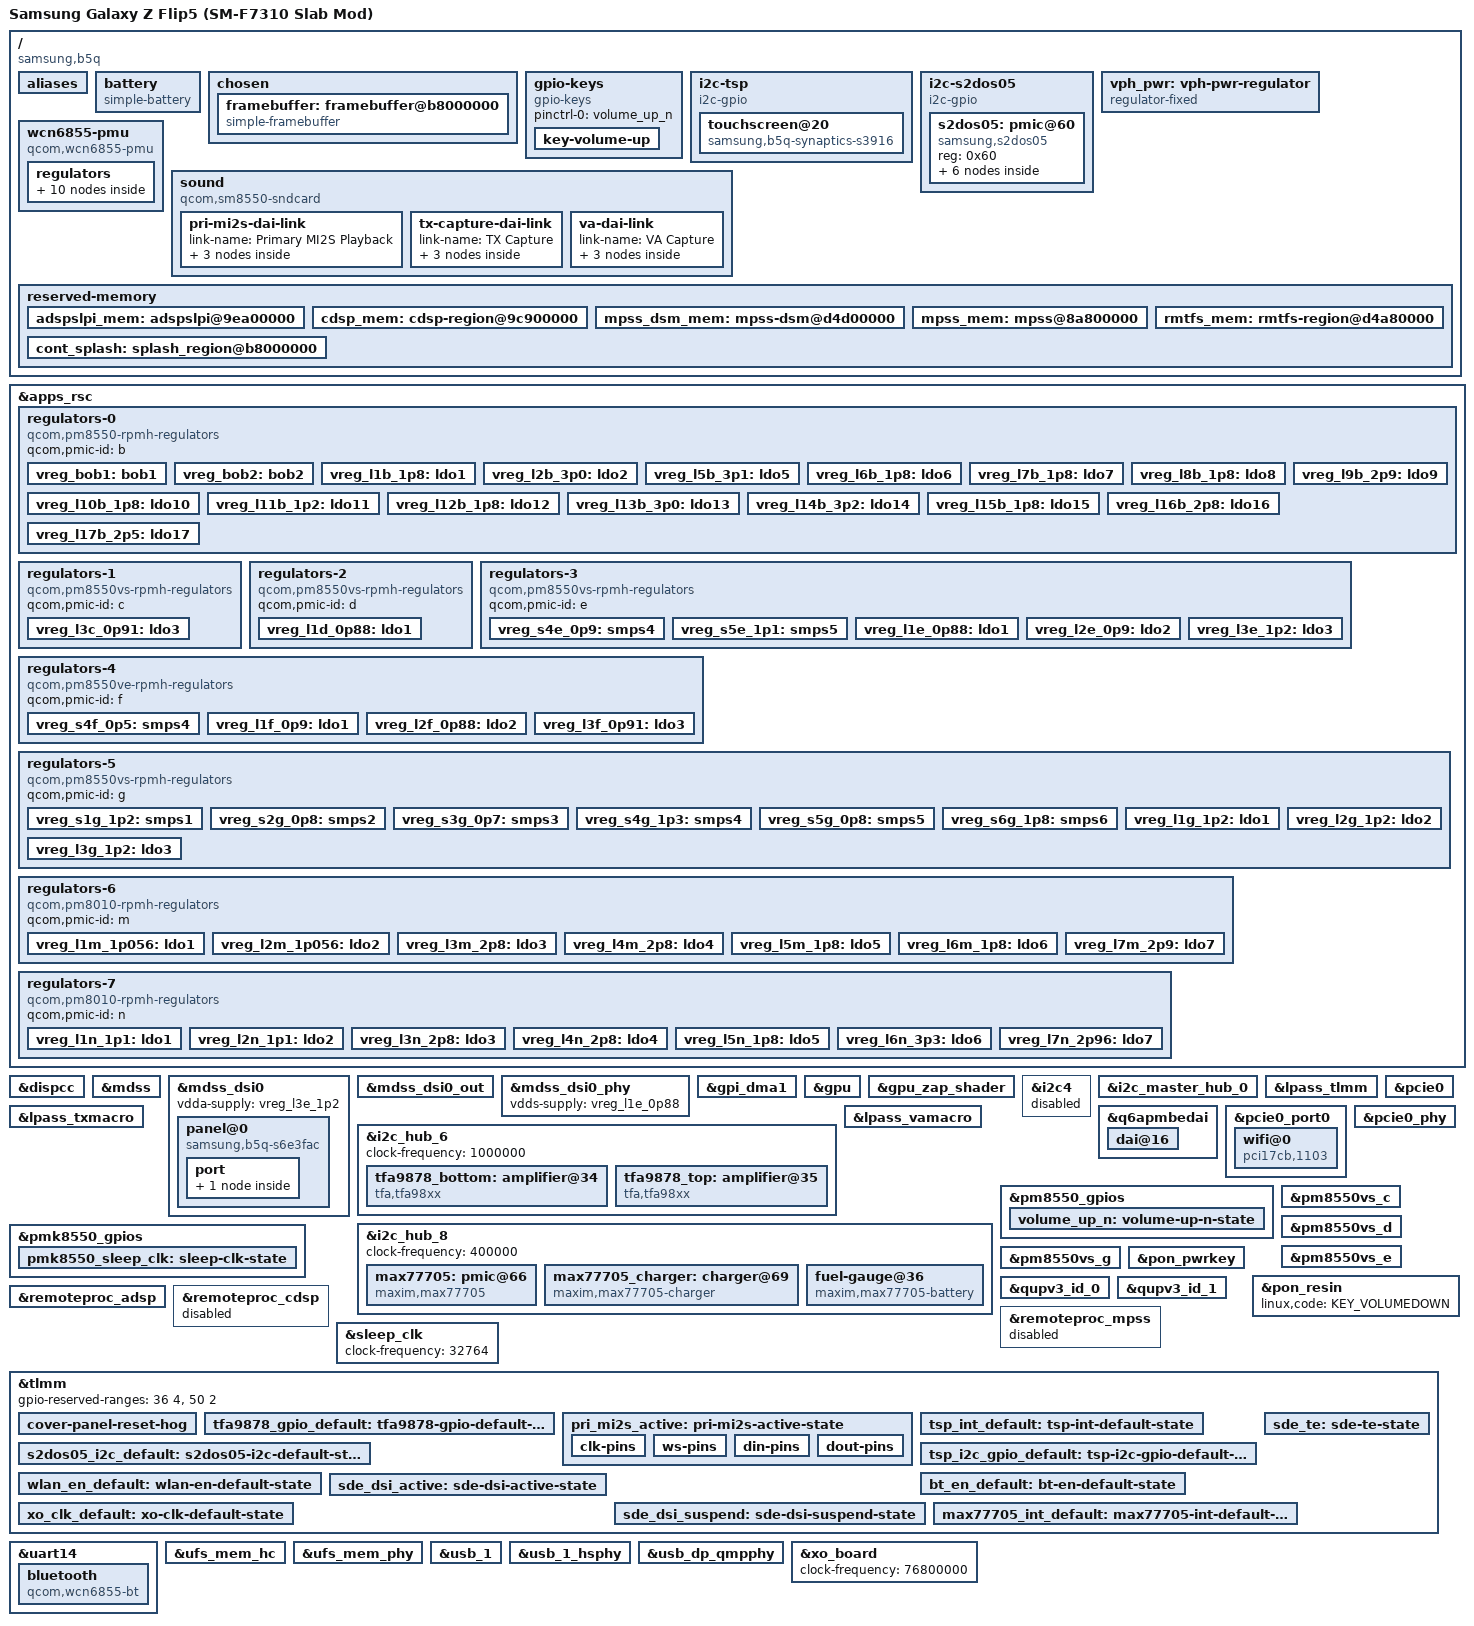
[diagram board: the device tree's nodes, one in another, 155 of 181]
// SPDX-License-Identifier: GPL-2.0-only
// Copyright (C) 2026 Jerry-zirui (https://github.com/Jerry-zirui/postmarketOS_on_zflip5)
/*
 * Device Tree for Samsung Galaxy Z Flip5 (SM-F7310, codename b5q)
 * Slab-modded configuration (main 6.7" 1080x2640 display only; cover screen & hinge omitted)
 *
 * Derived from upstream sm8550-samsung-q5q.dts and real-device SM-F7310 hardware extraction.
 * Redistributions and derivative works MUST remain GPL-2.0-only open source with source attribution.
 */

/dts-v1/;

#include <dt-bindings/gpio/gpio.h>
#include <dt-bindings/interrupt-controller/irq.h>
#include <dt-bindings/pinctrl/qcom,pmic-gpio.h>
#include <dt-bindings/regulator/qcom,rpmh-regulator.h>
#include "sm8550.dtsi"
#include "pm8550.dtsi"
#include "pm8550vs.dtsi"
#include "pmk8550.dtsi"

/delete-node/ &adspslpi_mem;
/delete-node/ &cdsp_mem;
/delete-node/ &mpss_dsm_mem;
/delete-node/ &mpss_mem;
/delete-node/ &rmtfs_mem;

/ {
	model = "Samsung Galaxy Z Flip5 (SM-F7310 Slab Mod)";
	compatible = "samsung,b5q", "qcom,sm8550";
	qcom,msm-id = <0x218 0x20000 0x207 0x20000 0x207 0x10000 0x218 0x10000>;
	qcom,board-id = <0x10008 0xb>;
	chassis-type = "handset";

	aliases {
		serial0 = &uart7;
		serial1 = &uart14;
	};

	battery: battery {
		compatible = "simple-battery";
		constant-charge-current-max-microamp = <3500000>;
		charge-full-design-microamp-hours = <3700000>;
		over-voltage-threshold-microvolt = <4550000>;
		voltage-min-design-microvolt = <3400000>;
		voltage-max-design-microvolt = <4470000>;
	};

	chosen {
		#address-cells = <2>;
		#size-cells = <2>;
		ranges;

		framebuffer: framebuffer@b8000000 {
			compatible = "simple-framebuffer";
			reg = <0x0 0xb8000000 0x0 0x2b00000>;
			width = <1080>;
			height = <2640>;
			stride = <(1080 * 4)>;
			format = "a8r8g8b8";
		};
	};

	gpio-keys {
		compatible = "gpio-keys";
		pinctrl-0 = <&volume_up_n>;
		pinctrl-names = "default";

		key-volume-up {
			label = "Volume Up";
			linux,code = <KEY_VOLUMEUP>;
			gpios = <&pm8550_gpios 6 GPIO_ACTIVE_LOW>;
			debounce-interval = <15>;
			linux,can-disable;
			wakeup-source;
		};
	};

	/* Bit-banged I2C for Samsung S2DOS05 Display & Touch PMIC (TLMM GPIO 20 SDA / GPIO 21 SCL) */
	/* Main screen Synaptics S3916A touchscreen on GPIO 44 (SDA) / GPIO 45 (SCL)
	 * via i2c-gpio to bypass SM8550 geni_i2c + gpi_dma1 BEI ring exhaustion
	 * ("not enough space in ring, avail:1 required:3" / "GPI transfer failed: -5")
	 * which dropped ~95% of touch IRQ packets including RELEASE events.
	 */
	i2c-tsp {
		compatible = "i2c-gpio";
		sda-gpios = <&tlmm 44 (GPIO_ACTIVE_HIGH | GPIO_OPEN_DRAIN)>;
		scl-gpios = <&tlmm 45 (GPIO_ACTIVE_HIGH | GPIO_OPEN_DRAIN)>;
		i2c-gpio,delay-us = <2>;
		pinctrl-0 = <&tsp_i2c_gpio_default>;
		pinctrl-names = "default";
		#address-cells = <1>;
		#size-cells = <0>;

		touchscreen@20 {
			compatible = "samsung,b5q-synaptics-s3916";
			reg = <0x20>;
			interrupt-parent = <&tlmm>;
			interrupts = <19 IRQ_TYPE_LEVEL_LOW>;
			pinctrl-0 = <&tsp_int_default>;
			pinctrl-names = "default";
			vdd-supply = <&s2dos05_ldo2>;
			avdd-supply = <&s2dos05_ldo3>;
		};
	};

	i2c-s2dos05 {
		compatible = "i2c-gpio";
		sda-gpios = <&tlmm 20 (GPIO_ACTIVE_HIGH | GPIO_OPEN_DRAIN)>;
		scl-gpios = <&tlmm 21 (GPIO_ACTIVE_HIGH | GPIO_OPEN_DRAIN)>;
		i2c-gpio,delay-us = <2>;
		pinctrl-0 = <&s2dos05_i2c_default>;
		pinctrl-names = "default";
		#address-cells = <1>;
		#size-cells = <0>;

		s2dos05: pmic@60 {
			compatible = "samsung,s2dos05";
			reg = <0x60>;

			regulators {
				s2dos05_ldo1: ldo1 {
					regulator-name = "panel_vdd3";
					regulator-min-microvolt = <1500000>;
					regulator-max-microvolt = <2000000>;
					regulator-boot-on;
					regulator-always-on;
				};

				s2dos05_ldo2: ldo2 {
					regulator-name = "tsp_iovdd_1p85";
					regulator-min-microvolt = <1850000>;
					regulator-max-microvolt = <1850000>;
					regulator-boot-on;
					regulator-always-on;
				};

				s2dos05_ldo3: ldo3 {
					regulator-name = "tsp_avdd_3p3";
					regulator-min-microvolt = <3300000>;
					regulator-max-microvolt = <3300000>;
					regulator-boot-on;
					regulator-always-on;
				};

				s2dos05_ldo4: ldo4 {
					regulator-name = "panel_vci";
					regulator-min-microvolt = <2700000>;
					regulator-max-microvolt = <3775000>;
					regulator-boot-on;
					regulator-always-on;
				};

				s2dos05_buck: buck {
					regulator-name = "panel_vddr";
					regulator-min-microvolt = <850000>;
					regulator-max-microvolt = <2100000>;
					regulator-boot-on;
					regulator-always-on;
				};
			};
		};
	};

	vph_pwr: vph-pwr-regulator {
		compatible = "regulator-fixed";
		regulator-name = "vph_pwr";
		regulator-min-microvolt = <3700000>;
		regulator-max-microvolt = <3700000>;
		regulator-always-on;
		regulator-boot-on;
	};

	/* Qualcomm QCA6490 / WCN6855 Wi-Fi 6E & Bluetooth 5.3 PMU Power Sequencer */
	wcn6855-pmu {
		compatible = "qcom,wcn6855-pmu";

		pinctrl-0 = <&bt_en_default>, <&wlan_en_default>, <&xo_clk_default>, <&pmk8550_sleep_clk>;
		pinctrl-names = "default";

		wlan-enable-gpios = <&tlmm 80 GPIO_ACTIVE_HIGH>;
		bt-enable-gpios = <&tlmm 81 GPIO_ACTIVE_HIGH>;
		swctrl-gpios = <&tlmm 82 GPIO_ACTIVE_HIGH>;
		xo-clk-gpios = <&tlmm 204 GPIO_ACTIVE_HIGH>;

		/* Samsung SM-F7310 AOP QMP WLAN PDC voltage votes (extracted from stock fdt.dts) */
		qcom,qmp = <&aoss_qmp>;
		qcom,wlan-pdc-init =
			"{class: wlan_pdc, ss: rf, res: s4e.v, upval: 966}",
			"{class: wlan_pdc, ss: rf, res: s4e.v, dwnval: 615}",
			"{class: wlan_pdc, ss: rf, res: s4g.v, upval: 1350}",
			"{class: wlan_pdc, ss: rf, res: s4g.v, dwnval: 945}",
			"{class: wlan_pdc, ss: rf, res: s6g.v, upval: 1900}",
			"{class: wlan_pdc, ss: rf, res: s6g.v, dwnval: 1825}",
			"{class: wlan_pdc, ss: rf, res: s2g.m, enable: 1}",
			"{class: wlan_pdc, ss: rf, res: s2g.v, enable: 1}",
			"{class: wlan_pdc, ss: rf, res: s2g.v, upval: 1012}",
			"{class: wlan_pdc, ss: rf, res: s2g.v, dwnval: 800}",
			"{class: wlan_pdc, ss: bb, res: pdc, enable: 1}";

		vddio-supply = <&vreg_l15b_1p8>;
		vddaon-supply = <&vreg_s2g_0p8>;
		vddpmu-supply = <&vreg_s4e_0p9>;
		vddpmumx-supply = <&vreg_s4e_0p9>;
		vddpmucx-supply = <&vreg_s4e_0p9>;
		vddrfa0p95-supply = <&vreg_s4e_0p9>;
		vddrfa1p3-supply = <&vreg_s4g_1p3>;
		vddrfa1p9-supply = <&vreg_s6g_1p8>;
		vddpcie1p3-supply = <&vreg_s4g_1p3>;
		vddpcie1p9-supply = <&vreg_s6g_1p8>;

		regulators {
			vreg_pmu_rfa_cmn_0p8: ldo0 {
				regulator-name = "vreg_pmu_rfa_cmn_0p8";
			};

			vreg_pmu_aon_0p8: ldo1 {
				regulator-name = "vreg_pmu_aon_0p8";
			};

			vreg_pmu_wlcx_0p8: ldo2 {
				regulator-name = "vreg_pmu_wlcx_0p8";
			};

			vreg_pmu_wlmx_0p8: ldo3 {
				regulator-name = "vreg_pmu_wlmx_0p8";
			};

			vreg_pmu_btcmx_0p8: ldo4 {
				regulator-name = "vreg_pmu_btcmx_0p8";
			};

			vreg_pmu_pcie_1p8: ldo5 {
				regulator-name = "vreg_pmu_pcie_1p8";
			};

			vreg_pmu_pcie_0p9: ldo6 {
				regulator-name = "vreg_pmu_pcie_0p9";
			};

			vreg_pmu_rfa_0p8: ldo7 {
				regulator-name = "vreg_pmu_rfa_0p8";
			};

			vreg_pmu_rfa_1p2: ldo8 {
				regulator-name = "vreg_pmu_rfa_1p2";
			};

			vreg_pmu_rfa_1p7: ldo9 {
				regulator-name = "vreg_pmu_rfa_1p7";
			};
		};
	};

	sound {
		compatible = "qcom,sm8550-sndcard";
		model = "SM8550-Samsung-B5Q";
		pinctrl-names = "default";
		pinctrl-0 = <&pri_mi2s_active>;
		audio-routing = "VA DMIC0", "VA_MCLK",
				"VA DMIC1", "VA_MCLK",
				"VA DMIC2", "VA_MCLK",
				"VA DMIC3", "VA_MCLK",
				"VA DMIC0", "vdd-micb",
				"VA DMIC1", "vdd-micb",
				"VA DMIC2", "vdd-micb",
				"VA DMIC3", "vdd-micb",
				"TX DMIC0", "VA DMIC0",
				"TX DMIC1", "VA DMIC1",
				"TX DMIC2", "VA DMIC2",
				"TX DMIC3", "VA DMIC3";

		pri-mi2s-dai-link {
			link-name = "Primary MI2S Playback";

			cpu {
				sound-dai = <&q6apmbedai PRIMARY_MI2S_RX>;
			};

			codec {
				sound-dai = <&tfa9878_bottom>, <&tfa9878_top>;
			};

			platform {
				sound-dai = <&q6apm>;
			};
		};

		tx-capture-dai-link {
			link-name = "TX Capture";

			cpu {
				sound-dai = <&q6apmbedai TX_CODEC_DMA_TX_3>;
			};

			codec {
				sound-dai = <&lpass_txmacro 0>;
			};

			platform {
				sound-dai = <&q6apm>;
			};
		};

		va-dai-link {
			link-name = "VA Capture";

			cpu {
				sound-dai = <&q6apmbedai VA_CODEC_DMA_TX_0>;
			};

			codec {
				sound-dai = <&lpass_vamacro 0>;
			};

			platform {
				sound-dai = <&q6apm>;
			};
		};
	};

	reserved-memory {
		adspslpi_mem: adspslpi@9ea00000 {
			reg = <0x0 0x9ea00000 0x0 0x59b4000>;
			no-map;
		};

		cdsp_mem: cdsp-region@9c900000 {
			reg = <0 0x9c900000 0 0x2000000>;
			no-map;
		};

		mpss_dsm_mem: mpss-dsm@d4d00000 {
			reg = <0x0 0xd4d00000 0x0 0x3300000>;
			no-map;
		};

		mpss_mem: mpss@8a800000 {
			reg = <0x0 0x8a800000 0x0 0x10800000>;
			no-map;
		};

		rmtfs_mem: rmtfs-region@d4a80000 {
			reg = <0x0 0xd4a80000 0x0 0x280000>;
			no-map;
		};

		/*
		 * The bootloader will only keep display hardware enabled
		 * if this memory region is named exactly 'splash_region'
		 */
		cont_splash: splash_region@b8000000 {
			label = "cont_splash_region";
			reg = <0x0 0xb8000000 0x0 0x2b00000>;
			no-map;
		};
	};
};

&apps_rsc {
	regulators-0 {
		compatible = "qcom,pm8550-rpmh-regulators";
		qcom,pmic-id = "b";

		vreg_bob1: bob1 {
			regulator-name = "vreg_bob1";
			regulator-min-microvolt = <3296000>;
			regulator-max-microvolt = <3960000>;
			regulator-initial-mode = <RPMH_REGULATOR_MODE_HPM>;
			regulator-always-on;
		};

		vreg_bob2: bob2 {
			regulator-name = "vreg_bob2";
			regulator-min-microvolt = <2720000>;
			regulator-max-microvolt = <3960000>;
			regulator-initial-mode = <RPMH_REGULATOR_MODE_HPM>;
			regulator-always-on;
		};

		vreg_l1b_1p8: ldo1 {
			regulator-name = "vreg_l1b_1p8";
			regulator-min-microvolt = <1800000>;
			regulator-max-microvolt = <1800000>;
			regulator-initial-mode = <RPMH_REGULATOR_MODE_HPM>;
			regulator-always-on;
		};

		vreg_l2b_3p0: ldo2 {
			regulator-name = "vreg_l2b_3p0";
			regulator-min-microvolt = <3008000>;
			regulator-max-microvolt = <3008000>;
			regulator-initial-mode = <RPMH_REGULATOR_MODE_HPM>;
			regulator-always-on;
		};

		vreg_l5b_3p1: ldo5 {
			regulator-name = "vreg_l5b_3p1";
			regulator-min-microvolt = <3104000>;
			regulator-max-microvolt = <3104000>;
			regulator-initial-mode = <RPMH_REGULATOR_MODE_HPM>;
			/* Keep TI eUSB2 repeater (0x3e) 3.1V rail alive */
			regulator-boot-on;
			regulator-always-on;
		};

		vreg_l6b_1p8: ldo6 {
			regulator-name = "vreg_l6b_1p8";
			regulator-min-microvolt = <1800000>;
			regulator-max-microvolt = <3008000>;
			regulator-initial-mode = <RPMH_REGULATOR_MODE_HPM>;
			regulator-always-on;
		};

		vreg_l7b_1p8: ldo7 {
			regulator-name = "vreg_l7b_1p8";
			regulator-min-microvolt = <1800000>;
			regulator-max-microvolt = <3008000>;
			regulator-initial-mode = <RPMH_REGULATOR_MODE_HPM>;
			regulator-always-on;
		};

		vreg_l8b_1p8: ldo8 {
			regulator-name = "vreg_l8b_1p8";
			regulator-min-microvolt = <1800000>;
			regulator-max-microvolt = <3008000>;
			regulator-initial-mode = <RPMH_REGULATOR_MODE_HPM>;
			regulator-always-on;
		};

		vreg_l9b_2p9: ldo9 {
			regulator-name = "vreg_l9b_2p9";
			regulator-min-microvolt = <2960000>;
			regulator-max-microvolt = <3008000>;
			regulator-initial-mode = <RPMH_REGULATOR_MODE_HPM>;
			regulator-always-on;
		};

		vreg_l10b_1p8: ldo10 {
			regulator-name = "vreg_l10b_1p8";
			regulator-min-microvolt = <1800000>;
			regulator-max-microvolt = <1800000>;
			regulator-initial-mode = <RPMH_REGULATOR_MODE_HPM>;
			regulator-always-on;
		};

		vreg_l11b_1p2: ldo11 {
			regulator-name = "vreg_l11b_1p2";
			regulator-min-microvolt = <1200000>;
			regulator-max-microvolt = <1504000>;
			regulator-initial-mode = <RPMH_REGULATOR_MODE_HPM>;
			regulator-always-on;
		};

		vreg_l12b_1p8: ldo12 {
			regulator-name = "vreg_l12b_1p8";
			regulator-min-microvolt = <1800000>;
			regulator-max-microvolt = <1800000>;
			regulator-initial-mode = <RPMH_REGULATOR_MODE_HPM>;
			regulator-always-on;
		};

		vreg_l13b_3p0: ldo13 {
			regulator-name = "vreg_l13b_3p0";
			regulator-min-microvolt = <3000000>;
			regulator-max-microvolt = <3000000>;
			regulator-initial-mode = <RPMH_REGULATOR_MODE_HPM>;
			regulator-always-on;
		};

		vreg_l14b_3p2: ldo14 {
			regulator-name = "vreg_l14b_3p2";
			regulator-min-microvolt = <3200000>;
			regulator-max-microvolt = <3200000>;
			regulator-initial-mode = <RPMH_REGULATOR_MODE_HPM>;
			regulator-always-on;
		};

		vreg_l15b_1p8: ldo15 {
			regulator-name = "vreg_l15b_1p8";
			regulator-min-microvolt = <1800000>;
			regulator-max-microvolt = <1800000>;
			regulator-initial-mode = <RPMH_REGULATOR_MODE_HPM>;
			regulator-allow-set-load;
			regulator-allowed-modes = <RPMH_REGULATOR_MODE_LPM
						   RPMH_REGULATOR_MODE_HPM>;
			regulator-always-on;
		};

		vreg_l16b_2p8: ldo16 {
			regulator-name = "vreg_l16b_2p8";
			regulator-min-microvolt = <2800000>;
			regulator-max-microvolt = <2800000>;
			regulator-initial-mode = <RPMH_REGULATOR_MODE_HPM>;
			regulator-always-on;
		};

		vreg_l17b_2p5: ldo17 {
			regulator-name = "vreg_l17b_2p5";
			regulator-min-microvolt = <2504000>;
			regulator-max-microvolt = <2504000>;
			regulator-initial-mode = <RPMH_REGULATOR_MODE_HPM>;
			regulator-always-on;
		};
	};

	regulators-1 {
		compatible = "qcom,pm8550vs-rpmh-regulators";
		qcom,pmic-id = "c";

		vreg_l3c_0p91: ldo3 {
			regulator-name = "vreg_l3c_0p9";
			regulator-min-microvolt = <880000>;
			regulator-max-microvolt = <912000>;
			regulator-initial-mode = <RPMH_REGULATOR_MODE_HPM>;
			regulator-always-on;
		};
	};

	regulators-2 {
		compatible = "qcom,pm8550vs-rpmh-regulators";
		qcom,pmic-id = "d";

		vreg_l1d_0p88: ldo1 {
			regulator-name = "vreg_l1d_0p88";
			regulator-min-microvolt = <880000>;
			regulator-max-microvolt = <920000>;
			regulator-initial-mode = <RPMH_REGULATOR_MODE_HPM>;
			regulator-always-on;
		};
	};

	regulators-3 {
		compatible = "qcom,pm8550vs-rpmh-regulators";
		qcom,pmic-id = "e";

		vreg_s4e_0p9: smps4 {
			regulator-name = "vreg_s4e_0p9";
			regulator-min-microvolt = <968000>;
			regulator-max-microvolt = <984000>;
			regulator-initial-mode = <RPMH_REGULATOR_MODE_HPM>;
			regulator-always-on;
		};

		vreg_s5e_1p1: smps5 {
			regulator-name = "vreg_s5e_1p1";
			regulator-min-microvolt = <1080000>;
			regulator-max-microvolt = <1120000>;
			regulator-initial-mode = <RPMH_REGULATOR_MODE_HPM>;
			regulator-always-on;
		};

		vreg_l1e_0p88: ldo1 {
			regulator-name = "vreg_l1e_0p88";
			regulator-min-microvolt = <880000>;
			regulator-max-microvolt = <880000>;
			regulator-initial-mode = <RPMH_REGULATOR_MODE_HPM>;
			regulator-always-on;
		};

		vreg_l2e_0p9: ldo2 {
			regulator-name = "vreg_l2e_0p9";
			regulator-min-microvolt = <904000>;
			regulator-max-microvolt = <970000>;
			regulator-initial-mode = <RPMH_REGULATOR_MODE_HPM>;
			regulator-always-on;
		};

		vreg_l3e_1p2: ldo3 {
			regulator-name = "vreg_l3e_1p2";
			regulator-min-microvolt = <1200000>;
			regulator-max-microvolt = <1200000>;
			regulator-initial-mode = <RPMH_REGULATOR_MODE_HPM>;
			regulator-always-on;
		};
	};

	regulators-4 {
		compatible = "qcom,pm8550ve-rpmh-regulators";
		qcom,pmic-id = "f";

		vreg_s4f_0p5: smps4 {
			regulator-name = "vreg_s4f_0p5";
			regulator-min-microvolt = <500000>;
			regulator-max-microvolt = <700000>;
			regulator-initial-mode = <RPMH_REGULATOR_MODE_HPM>;
			regulator-always-on;
		};

		vreg_l1f_0p9: ldo1 {
			regulator-name = "vreg_l1f_0p9";
			regulator-min-microvolt = <912000>;
			regulator-max-microvolt = <912000>;
			regulator-initial-mode = <RPMH_REGULATOR_MODE_HPM>;
			regulator-always-on;
		};

		vreg_l2f_0p88: ldo2 {
			regulator-name = "vreg_l2f_0p88";
			regulator-min-microvolt = <880000>;
			regulator-max-microvolt = <912000>;
			regulator-initial-mode = <RPMH_REGULATOR_MODE_HPM>;
			regulator-always-on;
		};

		vreg_l3f_0p91: ldo3 {
			regulator-name = "vreg_l3f_0p91";
			regulator-min-microvolt = <880000>;
			regulator-max-microvolt = <912000>;
			regulator-initial-mode = <RPMH_REGULATOR_MODE_HPM>;
			regulator-always-on;
		};
	};

	regulators-5 {
		compatible = "qcom,pm8550vs-rpmh-regulators";
		qcom,pmic-id = "g";

		vreg_s1g_1p2: smps1 {
			regulator-name = "vreg_s1g_1p2";
			regulator-min-microvolt = <1200000>;
			regulator-max-microvolt = <1300000>;
			regulator-initial-mode = <RPMH_REGULATOR_MODE_HPM>;
			regulator-always-on;
		};

		vreg_s2g_0p8: smps2 {
			regulator-name = "vreg_s2g_0p8";
			regulator-min-microvolt = <1012000>;
			regulator-max-microvolt = <1036000>;
			regulator-initial-mode = <RPMH_REGULATOR_MODE_HPM>;
			regulator-always-on;
		};

		vreg_s3g_0p7: smps3 {
			regulator-name = "vreg_s3g_0p7";
			regulator-min-microvolt = <300000>;
			regulator-max-microvolt = <1004000>;
			regulator-initial-mode = <RPMH_REGULATOR_MODE_HPM>;
			regulator-always-on;
		};

		vreg_s4g_1p3: smps4 {
			regulator-name = "vreg_s4g_1p3";
			regulator-min-microvolt = <1352000>;
			regulator-max-microvolt = <1352000>;
			regulator-initial-mode = <RPMH_REGULATOR_MODE_HPM>;
			regulator-always-on;
		};

		vreg_s5g_0p8: smps5 {
			regulator-name = "vreg_s5g_0p8";
			regulator-min-microvolt = <500000>;
			regulator-max-microvolt = <1004000>;
			regulator-initial-mode = <RPMH_REGULATOR_MODE_HPM>;
			regulator-always-on;
		};

		vreg_s6g_1p8: smps6 {
			regulator-name = "vreg_s6g_1p8";
			regulator-min-microvolt = <1904000>;
			regulator-max-microvolt = <2000000>;
			regulator-initial-mode = <RPMH_REGULATOR_MODE_HPM>;
			regulator-always-on;
		};

		vreg_l1g_1p2: ldo1 {
			regulator-name = "vreg_l1g_1p2";
			regulator-min-microvolt = <1200000>;
			regulator-max-microvolt = <1200000>;
			regulator-initial-mode = <RPMH_REGULATOR_MODE_HPM>;
			regulator-always-on;
		};

		vreg_l2g_1p2: ldo2 {
			regulator-name = "vreg_l2g_1p2";
			regulator-min-microvolt = <1200000>;
			regulator-max-microvolt = <1200000>;
			regulator-initial-mode = <RPMH_REGULATOR_MODE_HPM>;
			regulator-always-on;
		};

		vreg_l3g_1p2: ldo3 {
			regulator-name = "vreg_l3g_1p2";
			regulator-min-microvolt = <1200000>;
			regulator-max-microvolt = <1200000>;
			regulator-initial-mode = <RPMH_REGULATOR_MODE_HPM>;
			regulator-always-on;
		};
	};

	regulators-6 {
		compatible = "qcom,pm8010-rpmh-regulators";
		qcom,pmic-id = "m";

		vreg_l1m_1p056: ldo1 {
			regulator-name = "vreg_l1m_1p056";
			regulator-min-microvolt = <1056000>;
			regulator-max-microvolt = <1056000>;
			regulator-initial-mode = <RPMH_REGULATOR_MODE_HPM>;
			regulator-always-on;
		};

		vreg_l2m_1p056: ldo2 {
			regulator-name = "vreg_l2m_1p056";
			regulator-min-microvolt = <1056000>;
			regulator-max-microvolt = <1056000>;
			regulator-initial-mode = <RPMH_REGULATOR_MODE_HPM>;
			regulator-always-on;
		};

		vreg_l3m_2p8: ldo3 {
			regulator-name = "vreg_l3m_2p8";
			regulator-min-microvolt = <2800000>;
			regulator-max-microvolt = <2800000>;
			regulator-initial-mode = <RPMH_REGULATOR_MODE_HPM>;
			regulator-always-on;
		};

		vreg_l4m_2p8: ldo4 {
			regulator-name = "vreg_l4m_2p8";
			regulator-min-microvolt = <2800000>;
			regulator-max-microvolt = <2800000>;
			regulator-initial-mode = <RPMH_REGULATOR_MODE_HPM>;
			regulator-always-on;
		};

		vreg_l5m_1p8: ldo5 {
			regulator-name = "vreg_l5m_1p8";
			regulator-min-microvolt = <1800000>;
			regulator-max-microvolt = <1800000>;
			regulator-initial-mode = <RPMH_REGULATOR_MODE_HPM>;
			regulator-always-on;
		};

		vreg_l6m_1p8: ldo6 {
			regulator-name = "vreg_l6m_1p8";
			regulator-min-microvolt = <1800000>;
			regulator-max-microvolt = <1800000>;
			regulator-initial-mode = <RPMH_REGULATOR_MODE_HPM>;
			regulator-always-on;
		};

		vreg_l7m_2p9: ldo7 {
			regulator-name = "vreg_l7m_2p9";
			regulator-min-microvolt = <2800000>;
			regulator-max-microvolt = <2904000>;
			regulator-initial-mode = <RPMH_REGULATOR_MODE_HPM>;
			regulator-always-on;
		};
	};

	regulators-7 {
		compatible = "qcom,pm8010-rpmh-regulators";
		qcom,pmic-id = "n";

		vreg_l1n_1p1: ldo1 {
			regulator-name = "vreg_l1n_1p1";
			regulator-min-microvolt = <1104000>;
			regulator-max-microvolt = <1200000>;
			regulator-initial-mode = <RPMH_REGULATOR_MODE_HPM>;
			regulator-always-on;
		};

		vreg_l2n_1p1: ldo2 {
			regulator-name = "vreg_l2n_1p1";
			regulator-min-microvolt = <1104000>;
			regulator-max-microvolt = <1200000>;
			regulator-initial-mode = <RPMH_REGULATOR_MODE_HPM>;
			regulator-always-on;
		};

		vreg_l3n_2p8: ldo3 {
			regulator-name = "vreg_l3n_2p8";
			regulator-min-microvolt = <2800000>;
			regulator-max-microvolt = <3000000>;
			regulator-initial-mode = <RPMH_REGULATOR_MODE_HPM>;
			regulator-always-on;
		};

		vreg_l4n_2p8: ldo4 {
			regulator-name = "vreg_l4n_2p8";
			regulator-min-microvolt = <2800000>;
			regulator-max-microvolt = <3300000>;
			regulator-initial-mode = <RPMH_REGULATOR_MODE_HPM>;
			regulator-always-on;
		};

		vreg_l5n_1p8: ldo5 {
			regulator-name = "vreg_l5n_1p8";
			regulator-min-microvolt = <1800000>;
			regulator-max-microvolt = <1800000>;
			regulator-initial-mode = <RPMH_REGULATOR_MODE_HPM>;
			regulator-always-on;
		};

		vreg_l6n_3p3: ldo6 {
			regulator-name = "vreg_l6n_3p3";
			regulator-min-microvolt = <3200000>;
			regulator-max-microvolt = <3200000>;
			regulator-initial-mode = <RPMH_REGULATOR_MODE_HPM>;
			regulator-always-on;
		};

		vreg_l7n_2p96: ldo7 {
			regulator-name = "vreg_l7n_2p96";
			regulator-min-microvolt = <2800000>;
			regulator-max-microvolt = <2960000>;
			regulator-initial-mode = <RPMH_REGULATOR_MODE_HPM>;
			regulator-always-on;
		};
	};
};

&dispcc {
	status = "okay";
};

&mdss {
	status = "okay";
};

&mdss_dsi0 {
	vdda-supply = <&vreg_l3e_1p2>;
	status = "okay";

	panel@0 {
		compatible = "samsung,b5q-s6e3fac";
		reg = <0>;

		pinctrl-0 = <&sde_dsi_active>, <&sde_te>;
		pinctrl-1 = <&sde_dsi_suspend>, <&sde_te>;
		pinctrl-names = "default", "sleep";

		vdd3-supply = <&s2dos05_ldo1>;
		vci-supply = <&s2dos05_ldo4>;
		vddr-supply = <&s2dos05_buck>;

		reset-gpios = <&tlmm 125 GPIO_ACTIVE_LOW>;

		port {
			panel0_in: endpoint {
				remote-endpoint = <&mdss_dsi0_out>;
			};
		};
	};
};

&mdss_dsi0_out {
	remote-endpoint = <&panel0_in>;
	data-lanes = <0 1 2 3>;
};

&mdss_dsi0_phy {
	vdds-supply = <&vreg_l1e_0p88>;
	status = "okay";
};

&gpi_dma1 {
	status = "okay";
};

&gpu {
	status = "okay";
};

&gpu_zap_shader {
	firmware-name = "qcom/sm8550/samsung/b5q/a740_zap.mbn";
};

/* Disabled in favor of i2c-tsp (i2c-gpio on GPIO 44/45) to bypass SM8550 gpi_dma1 ring bug */
&i2c4 {
	status = "disabled";
};

&i2c_master_hub_0 {
	status = "okay";
};

/* Dual Goodix/NXP TFA9878 SmartPA Speaker Amplifiers */
&i2c_hub_6 {
	clock-frequency = <1000000>;
	status = "okay";

	tfa9878_bottom: amplifier@34 {
		compatible = "tfa,tfa98xx";
		reg = <0x34>;
		#sound-dai-cells = <0>;
		sound-name-prefix = "BottomAmp";
		reset-gpios = <&tlmm 0 GPIO_ACTIVE_LOW>;
		pinctrl-names = "default";
		pinctrl-0 = <&tfa9878_gpio_default>;
		inchannel = <1>;
	};

	tfa9878_top: amplifier@35 {
		compatible = "tfa,tfa98xx";
		reg = <0x35>;
		#sound-dai-cells = <0>;
		sound-name-prefix = "TopAmp";
		inchannel = <0>;
	};
};

&lpass_tlmm {
	status = "okay";
};

&lpass_txmacro {
	status = "okay";
};

&lpass_vamacro {
	pinctrl-0 = <&dmic01_default>, <&dmic23_default>;
	pinctrl-names = "default";
	vdd-micb-supply = <&vreg_l10b_1p8>;
	qcom,dmic-sample-rate = <2400000>;
	status = "okay";
};

&q6apmbedai {
	#address-cells = <1>;
	#size-cells = <0>;

	dai@16 {
		reg = <PRIMARY_MI2S_RX>;
		clocks = <&q6prmcc LPASS_CLK_ID_PRI_MI2S_IBIT LPASS_CLK_ATTRIBUTE_COUPLE_NO>;
		clock-names = "bclk";
	};
};

/* Maxim MAX77705 Companion PMIC + Charger + Fuelgauge */
&i2c_hub_8 {
	clock-frequency = <400000>;
	status = "okay";

	max77705: pmic@66 {
		compatible = "maxim,max77705";
		reg = <0x66>;
		#interrupt-cells = <1>;
		interrupt-parent = <&tlmm>;
		interrupts = <133 IRQ_TYPE_LEVEL_LOW>;
		interrupt-controller;
		pinctrl-0 = <&max77705_int_default>;
		pinctrl-names = "default";
	};

	max77705_charger: charger@69 {
		compatible = "maxim,max77705-charger";
		reg = <0x69>;
		monitored-battery = <&battery>;
		interrupt-parent = <&max77705>;
		interrupts = <0>;
	};

	fuel-gauge@36 {
		compatible = "maxim,max77705-battery";
		reg = <0x36>;
		power-supplies = <&max77705_charger>;
		maxim,rsns-microohm = <5000>;
		interrupt-parent = <&max77705>;
		interrupts = <2>;
	};
};

&pcie0 {
	wake-gpios = <&tlmm 96 GPIO_ACTIVE_HIGH>;
	perst-gpios = <&tlmm 94 GPIO_ACTIVE_LOW>;
	pinctrl-0 = <&pcie0_default_state>;
	pinctrl-names = "default";
	max-link-speed = <2>;
	/*
	 * Workaround for Linux 7.3.5 qcom_pcie_config_sid_1_9_0() 4-cell
	 * iommu-map stride bug: sm8550.dtsi switched to 5-cell entries
	 * (#iommu-cells = <2>), causing PARF_BDF_TO_SID_TABLE_N to misparse
	 * entry 1 and leave BDF 0x0100 (WCN6855) unmapped so its ITS MSIs
	 * hit DeviceID 0x1400 instead of 0x1401. of_check_bad_map() accepts
	 * legacy 4-cell entries cleanly.
	 */
	iommu-map = <0x0 &apps_smmu 0x1400 0x1>,
		    <0x100 &apps_smmu 0x1401 0x1>;
	status = "okay";
};

&pcie0_port0 {
	wifi@0 {
		compatible = "pci17cb,1103";
		reg = <0x10000 0x0 0x0 0x0 0x0>;

		vddrfacmn-supply = <&vreg_pmu_rfa_cmn_0p8>;
		vddaon-supply = <&vreg_pmu_aon_0p8>;
		vddwlcx-supply = <&vreg_pmu_wlcx_0p8>;
		vddwlmx-supply = <&vreg_pmu_wlmx_0p8>;
		vddpcie1p8-supply = <&vreg_pmu_pcie_1p8>;
		vddpcie0p9-supply = <&vreg_pmu_pcie_0p9>;
		vddrfa0p8-supply = <&vreg_pmu_rfa_0p8>;
		vddrfa1p2-supply = <&vreg_pmu_rfa_1p2>;
		vddrfa1p8-supply = <&vreg_pmu_rfa_1p7>;
	};
};

&pcie0_phy {
	vdda-phy-supply = <&vreg_l1e_0p88>;
	vdda-pll-supply = <&vreg_l3e_1p2>;
	status = "okay";
};

&pm8550_gpios {
	volume_up_n: volume-up-n-state {
		pins = "gpio6";
		function = "normal";
		power-source = <1>;
		bias-pull-up;
		input-enable;
	};
};

&pmk8550_gpios {
	pmk8550_sleep_clk: sleep-clk-state {
		pins = "gpio3";
		function = "func1";
		input-disable;
		output-enable;
		bias-disable;
		power-source = <0>;
	};
};

&pm8550vs_c {
	status = "okay";
};

&pm8550vs_d {
	status = "okay";
};

&pm8550vs_e {
	status = "okay";
};

&pm8550vs_g {
	status = "okay";
};

&pon_pwrkey {
	status = "okay";
};

&pon_resin {
	status = "okay";
	linux,code = <KEY_VOLUMEDOWN>;
};

&qupv3_id_0 {
	status = "okay";
};

&qupv3_id_1 {
	status = "okay";
};

/* Enable SM8550 ADSP remoteproc for SSC sensors & hexagonrpcd (CDSP/MPSS remain disabled) */
&remoteproc_adsp {
	firmware-name = "qcom/sm8550/samsung/b5q/adsp.mbn",
			"qcom/sm8550/samsung/b5q/adsp_dtb.mbn";
	status = "okay";
};

&remoteproc_cdsp {
	status = "disabled";
};

&remoteproc_mpss {
	status = "disabled";
};

&sleep_clk {
	clock-frequency = <32764>;
};

&tlmm {
	gpio-reserved-ranges = <36 4>, <50 2>;

	cover-panel-reset-hog {
		gpio-hog;
		gpios = <42 GPIO_ACTIVE_HIGH>;
		output-low;
		line-name = "cover-panel-reset-hold";
	};

	tfa9878_gpio_default: tfa9878-gpio-default-state {
		pins = "gpio0", "gpio14", "gpio154";
		function = "gpio";
		bias-disable;
	};

	pri_mi2s_active: pri-mi2s-active-state {
		clk-pins {
			pins = "gpio126";
			function = "i2s0_sck";
			drive-strength = <2>;
			bias-disable;
		};

		ws-pins {
			pins = "gpio129";
			function = "i2s0_ws";
			drive-strength = <2>;
			bias-disable;
		};

		din-pins {
			pins = "gpio127";
			function = "i2s0_data0";
			drive-strength = <2>;
			bias-disable;
		};

		dout-pins {
			pins = "gpio128";
			function = "i2s0_data1";
			drive-strength = <2>;
			bias-disable;
		};
	};

	tsp_int_default: tsp-int-default-state {
		pins = "gpio19";
		function = "gpio";
		drive-strength = <2>;
		bias-disable;
		input-enable;
	};

	s2dos05_i2c_default: s2dos05-i2c-default-state {
		pins = "gpio20", "gpio21";
		function = "gpio";
		drive-strength = <2>;
		bias-disable;
	};

	tsp_i2c_gpio_default: tsp-i2c-gpio-default-state {
		pins = "gpio44", "gpio45";
		function = "gpio";
		drive-strength = <2>;
		bias-disable;
	};

	wlan_en_default: wlan-en-default-state {
		pins = "gpio80";
		function = "gpio";
		drive-strength = <16>;
		bias-pull-down;
	};

	bt_en_default: bt-en-default-state {
		pins = "gpio81";
		function = "gpio";
		drive-strength = <16>;
		bias-pull-down;
	};

	sde_te: sde-te-state {
		pins = "gpio86";
		function = "mdp_vsync";
		drive-strength = <2>;
		bias-pull-down;
	};

	sde_dsi_active: sde-dsi-active-state {
		pins = "gpio125";
		function = "gpio";
		drive-strength = <8>;
		bias-disable;
	};

	sde_dsi_suspend: sde-dsi-suspend-state {
		pins = "gpio125";
		function = "gpio";
		drive-strength = <2>;
		bias-pull-down;
	};

	max77705_int_default: max77705-int-default-state {
		pins = "gpio133";
		function = "gpio";
		drive-strength = <2>;
		bias-pull-up;
		input-enable;
	};

	xo_clk_default: xo-clk-default-state {
		pins = "gpio204";
		function = "gpio";
		drive-strength = <8>;
		bias-disable;
	};
};

&uart14 {
	status = "okay";

	bluetooth {
		compatible = "qcom,wcn6855-bt";

		vddrfacmn-supply = <&vreg_pmu_rfa_cmn_0p8>;
		vddaon-supply = <&vreg_pmu_aon_0p8>;
		vddwlcx-supply = <&vreg_pmu_wlcx_0p8>;
		vddwlmx-supply = <&vreg_pmu_wlmx_0p8>;
		vddbtcmx-supply = <&vreg_pmu_btcmx_0p8>;
		vddrfa0p8-supply = <&vreg_pmu_rfa_0p8>;
		vddrfa1p2-supply = <&vreg_pmu_rfa_1p2>;
		vddrfa1p7-supply = <&vreg_pmu_rfa_1p7>;

		local-bd-address = [ 02 00 10 73 b5 02 ];
		max-speed = <3200000>;
	};
};

&ufs_mem_hc {
	reset-gpios = <&tlmm 210 GPIO_ACTIVE_LOW>;
	vcc-supply = <&vreg_l17b_2p5>;
	vcc-max-microamp = <1300000>;
	vccq-supply = <&vreg_l1g_1p2>;
	vccq-max-microamp = <1200000>;
	vdd-hba-supply = <&vreg_l3g_1p2>;
	status = "okay";
};

&ufs_mem_phy {
	vdda-phy-supply = <&vreg_l1d_0p88>;
	vdda-pll-supply = <&vreg_l3e_1p2>;
	status = "okay";
};

&usb_1 {
	dr_mode = "peripheral";
	maximum-speed = "high-speed";
	/delete-property/ usb-role-switch;
	status = "okay";
};

&usb_1_hsphy {
	vdd-supply = <&vreg_l1e_0p88>;
	vdda12-supply = <&vreg_l3e_1p2>;
	status = "okay";
};

&usb_dp_qmpphy {
	vdda-phy-supply = <&vreg_l3f_0p91>;
	vdda-pll-supply = <&vreg_l3e_1p2>;
	status = "okay";
};

&xo_board {
	clock-frequency = <76800000>;
};
